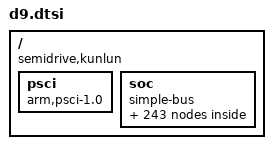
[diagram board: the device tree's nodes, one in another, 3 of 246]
/*
 * Semidrive D9 platform DTS file
 *
 * Copyright (C) 2021, Semidrive  Communications Inc.
 *
 * This file is licensed under a dual GPLv2 or X11 license.
 */

#include <dt-bindings/interrupt-controller/arm-gic.h>
#include <dt-bindings/display/dpu-sdx9.h>
#include <dt-bindings/clk/x9-clk.h>
#include <dt-bindings/dma/x9-dmac-slave-id.h>
#include <dt-bindings/gpio/gpio.h>
#include <dt-bindings/soc/sdrv-common-reg.h>
#include <dt-bindings/soc/sdrv,scr_signal.h>
#include <dt-bindings/soc/sdrv-pfm-group.h>
#include <dt-bindings/thermal/thermal.h>
#include "d9_clk_base.dtsi"
#include "d9_opp.dtsi"
/ {
	compatible = "semidrive,kunlun";
	#address-cells = <2>;
	#size-cells = <2>;

	psci: psci {
		compatible	= "arm,psci-1.0";
		method		= "smc";
		cpu_on		= <0xc4000003>;
		cpu_off		= <0x84000002>;
		cpu_suspend	= <0xc4000001>;
	};

	soc {
		compatible = "simple-bus";
		#address-cells = <2>;
		#size-cells = <2>;
		ranges;

		smmu: smmu@35800000 {
			compatible = "arm,smmu-v3";
			reg = <0x0 0x35800000 0x0 0x800000>;
			interrupts = <0 277 IRQ_TYPE_EDGE_RISING>,
					<0 285 IRQ_TYPE_EDGE_RISING>,
					<0 278 IRQ_TYPE_EDGE_RISING>,
					<0 280 IRQ_TYPE_EDGE_RISING>;
			interrupt-names = "eventq", "priq", "cmdq-sync", "gerror";
			#iommu-cells = <1>;
			status = "disabled";
		};

		uart1: serial@300f0000 {
			compatible = "snps,dw-apb-uart";
			reg = <0 0x300f0000 0 0x100>;
			reg-shift=<2>;
			reg-io-width=<4>;
			interrupts = <0 16 4>;
			clock-frequency=<80000000>;
/*			clocks = <&UART_SEC1_10>;*/
			clock-names = "baudclk";
			status = "disabled";
		};

		uart2: serial@30100000 {
			compatible = "snps,dw-apb-uart";
			reg = <0 0x30100000 0 0x100>;
			reg-shift=<2>;
			reg-io-width=<4>;
			interrupts = <0 17 4>;
			clock-frequency=<80000000>;
/*			clocks = <&UART_SEC1_10>;*/
			clock-names = "baudclk";
			status = "disabled";
		};

		uart4: serial@30120000 {
			compatible = "snps,dw-apb-uart";
			reg = <0 0x30120000 0 0x100>;
			reg-shift=<2>;
			reg-io-width=<4>;
			interrupts = <0 19 4>;
			clock-frequency=<80000000>;
/*			clocks = <&UART_SEC1_10>;*/
			clock-names = "baudclk";
			status = "disabled";
		};

		uart5: serial@30130000 {
			compatible = "snps,dw-apb-uart";
			reg = <0 0x30130000 0 0x100>;
			reg-shift=<2>;
			reg-io-width=<4>;
			interrupts = <0 20 4>;
			clock-frequency=<80000000>;
/*			clocks = <&UART_SEC1_10>;*/
			clock-names = "baudclk";
			status = "disabled";
		};

		uart6: serial@30140000 {
			compatible = "snps,dw-apb-uart";
			reg = <0 0x30140000 0 0x100>;
			reg-shift=<2>;
			reg-io-width=<4>;
			interrupts = <0 21 4>;
			clock-frequency=<80000000>;
/*			clocks = <&UART_SEC1_10>;*/
			clock-names = "baudclk";
			status = "disabled";
		};

		uart7: serial@30150000 {
			compatible = "snps,dw-apb-uart";
			reg = <0 0x30150000 0 0x100>;
			reg-shift=<2>;
			reg-io-width=<4>;
			interrupts = <0 22 4>;
			clock-frequency=<80000000>;
/*			clocks = <&UART_SEC1_10>;*/
			clock-names = "baudclk";
			status = "disabled";
		};

		uart8: serial@30160000 {
			compatible = "snps,dw-apb-uart";
			reg = <0 0x30160000 0 0x100>;
			reg-shift=<2>;
			reg-io-width=<4>;
			interrupts = <0 23 4>;
			clock-frequency=<80000000>;
/*			clocks = <&UART_SEC1_10>;*/
			clock-names = "baudclk";
			status = "disabled";
		};

		uart9: serial@304c0000 {
			compatible = "snps,dw-apb-uart";
			reg = <0 0x304c0000 0 0x100>;
			reg-shift=<2>;
			reg-io-width=<4>;
			interrupts = <0 24 4>;
			clock-frequency=<60000000>;
			clocks = <&UART_SEC0_9>;
			clock-names = "baudclk";
			status = "disabled";
		};

		uart10: serial@304d0000 {
			compatible = "snps,dw-apb-uart";
			reg = <0 0x304d0000 0 0x100>;
			reg-shift=<2>;
			reg-io-width=<4>;
			interrupts = <0 25 4>;
			clock-frequency=<60000000>;
			clocks = <&UART_SEC1_10>;
			clock-names = "baudclk";
			status = "disabled";
		};

		uart11: serial@304e0000 {
			compatible = "snps,dw-apb-uart";
			reg = <0 0x304e0000 0 0x100>;
			reg-shift=<2>;
			reg-io-width=<4>;
			interrupts = <0 26 4>;
			clock-frequency=<60000000>;
			clocks = <&UART_SEC0_11>;
			clock-names = "baudclk";
			status = "disabled";
		};

		uart12: serial@304f0000 {
			compatible = "snps,dw-apb-uart";
			reg = <0 0x304f0000 0 0x100>;
			reg-shift=<2>;
			reg-io-width=<4>;
			interrupts = <0 27 4>;
			clock-frequency=<60000000>;
			clocks = <&UART_SEC1_12>;
			clock-names = "baudclk";
			status = "disabled";
		};

		uart13: serial@30500000 {
			compatible = "snps,dw-apb-uart";
			reg = <0 0x30500000 0 0x100>;
			reg-shift=<2>;
			reg-io-width=<4>;
			interrupts = <0 28 4>;
			clock-frequency=<60000000>;
			clocks = <&UART_SEC0_13>;
			clock-names = "baudclk";
			status = "disabled";
		};

		uart14: serial@30510000 {
			compatible = "snps,dw-apb-uart";
			reg = <0 0x30510000 0 0x100>;
			reg-shift=<2>;
			reg-io-width=<4>;
			interrupts = <0 29 4>;
			clock-frequency=<60000000>;
			clocks = <&UART_SEC1_14>;
			clock-names = "baudclk";
			status = "disabled";
		};

		uart15: serial@30520000 {
			compatible = "snps,dw-apb-uart";
			reg = <0 0x30520000 0 0x100>;
			reg-shift=<2>;
			reg-io-width=<4>;
			interrupts = <0 30 4>;
			clock-frequency=<60000000>;
			clocks = <&UART_SEC0_15>;
			clock-names = "baudclk";
			status = "disabled";
		};

		uart16: serial@30530000 {
			compatible = "snps,dw-apb-uart";
			reg = <0 0x30530000 0 0x100>;
			reg-shift=<2>;
			reg-io-width=<4>;
			interrupts = <0 31 4>;
			clock-frequency=<60000000>;
			clocks = <&UART_SEC1_16>;
			clock-names = "baudclk";
			status = "disabled";
		};

		generic_timer: timer {
			compatible = "arm,armv8-timer";
			interrupts = <1 13 (GIC_CPU_MASK_SIMPLE(6) | IRQ_TYPE_LEVEL_LOW)>,
				<1 14 (GIC_CPU_MASK_SIMPLE(6) | IRQ_TYPE_LEVEL_LOW)>,
				<1 11 (GIC_CPU_MASK_SIMPLE(6) | IRQ_TYPE_LEVEL_LOW)>,
				<1 10 (GIC_CPU_MASK_SIMPLE(6) | IRQ_TYPE_LEVEL_LOW)>;
			clock-frequency = <SYS_CNT_FREQ>;
			status = "disabled";
		};

		timer3: timer@0x308b0000 {
			compatible = "sd,sd-timer", "sd,sd-pwm-capture";
			#address-cells = <2>;
			#size-cells = <2>;
			reg = <0 0x308B0000 0 0x10000>;
			interrupts = <0 197 4>;
			clock-frequency = <24000000>;
			clocks=<&TIMER3>;
			status = "disabled";
		};

		timer4: timer@0x308c0000 {
			compatible = "sd,sd-timer", "sd,sd-pwm-capture";
			#address-cells = <2>;
			#size-cells = <2>;
			reg = <0 0x308C0000 0 0x10000>;
			interrupts = <0 199 4>;
			clock-frequency = <24000000>;
			clocks=<&TIMER4>;
			status = "disabled";
		};

		timer5: timer@0x308d0000 {
			compatible = "sd,sd-timer", "sd,sd-pwm-capture";
			#address-cells = <2>;
			#size-cells = <2>;
			reg = <0 0x308D0000 0 0x10000>;
			interrupts = <0 201 4>;
			clock-frequency = <24000000>;
			clocks=<&TIMER5>;
			status = "disabled";
		};

		timer6: timer@0x308e0000 {
			compatible = "sd,sd-timer", "sd,sd-pwm-capture";
			#address-cells = <2>;
			#size-cells = <2>;
			reg = <0 0x308E0000 0 0x10000>;
			interrupts = <0 203 4>;
			clock-frequency = <24000000>;
			clocks=<&TIMER6>;
			status = "disabled";
		};

		timer7: timer@0x308f0000 {
			compatible = "sd,sd-timer", "sd,sd-pwm-capture";
			#address-cells = <2>;
			#size-cells = <2>;
			reg = <0 0x308F0000 0 0x10000>;
			interrupts = <0 205 4>;
			clock-frequency = <24000000>;
			clocks=<&TIMER7>;
			status = "disabled";
		};

		timer8: timer@0x30900000 {
			compatible = "sd,sd-timer", "sd,sd-pwm-capture";
			#address-cells = <2>;
			#size-cells = <2>;
			reg = <0 0x30900000 0 0x10000>;
			interrupts = <0 207 4>;
			clock-frequency = <24000000>;
			clocks=<&TIMER8>;
			status = "disabled";
		};

		adc_ap: adc@0x30860000 {
			compatible = "sdrv,sdrv-adc";
			reg = <0 0x30860000 0 0x10000>;
			interrupts = <GIC_SPI 208 IRQ_TYPE_LEVEL_HIGH>;
            		#io-channel-cells = <1>;
			clocks = <&ADC>;
			clock-names = "adc-clk";
			status = "disabled";
		};

		pwm1:pwm@301a0000 {
				compatible = "sd,sd-pwm-playback";
				#address-cells = <2>;
				#size-cells = <2>;
				reg = <0 0x301a0000 0 0x10000>;
				interrupts = <0 209 4>;
				clock-frequency = <398000000>;
				clocks=<&PWM1>;
				clock-names = "plbkclk";
				status = "disabled";
		};

		pwm2:pwm@301b0000 {
				compatible = "sd,sd-pwm-playback";
				#address-cells = <2>;
				#size-cells = <2>;
				reg = <0 0x301b0000 0 0x10000>;
				interrupts = <0 210 4>;
				clock-frequency = <398000000>;
				clocks=<&PWM2>;
				clock-names = "plbkclk";
				status = "disabled";
		};

		pwm3:pwm@0x30910000 {
			compatible = "sd,sd-pwm-playback";
			#address-cells = <2>;
			#size-cells = <2>;
			reg = <0 0x30910000 0 0x10000>;
			interrupts = <0 211 4>;
			clock-frequency = <398000000>;
			clocks=<&PWM3>;
			clock-names = "plbkclk";
			status = "disabled";
		};

		pwm4:pwm@0x30920000 {
			compatible = "sd,sd-pwm-playback";
			#address-cells = <2>;
			#size-cells = <2>;
			reg = <0 0x30920000 0 0x10000>;
			interrupts = <0 212 4>;
			clock-frequency = <398000000>;
			clocks=<&PWM4>;
			clock-names = "plbkclk";
			status = "disabled";
		};

		pwm5:pwm@0x30930000 {
			compatible = "sd,sd-pwm-playback";
			#address-cells = <2>;
			#size-cells = <2>;
			reg = <0 0x30930000 0 0x10000>;
			interrupts = <0 213 4>;
			clock-frequency = <398000000>;
			clocks=<&PWM5>;
			clock-names = "plbkclk";
			status = "disabled";
		};

		pwm6:pwm@0x30940000 {
			compatible = "sd,sd-pwm-playback";
			#address-cells = <2>;
			#size-cells = <2>;
			reg = <0 0x30940000 0 0x10000>;
			interrupts = <0 214 4>;
			clock-frequency = <398000000>;
			clocks=<&PWM6>;
			clock-names = "plbkclk";
			status = "disabled";
		};

		pwm7:pwm@0x30950000 {
			compatible = "sd,sd-pwm-playback";
			#address-cells = <2>;
			#size-cells = <2>;
			reg = <0 0x30950000 0 0x10000>;
			interrupts = <0 215 4>;
			clock-frequency = <398000000>;
			clocks=<&PWM7>;
			clock-names = "plbkclk";
			status = "disabled";
		};

		pwm8:pwm@0x30960000 {
			compatible = "sd,sd-pwm-playback";
			#address-cells = <2>;
			#size-cells = <2>;
			reg = <0 0x30960000 0 0x10000>;
			interrupts = <0 216 4>;
			clock-frequency = <398000000>;
			clocks=<&PWM8>;
			clock-names = "plbkclk";
			status = "disabled";
		};

		i2c1:i2c@300b0000 {
			compatible = "snps,designware-i2c";
			reg = <0x0 0x300b0000 0x0 0x1000>;
			interrupts = <0 32 4>;
			#address-cells = <1>;
			#size-cells = <0>;
			clocks=<&I2C_SEC0_5>;
			clock-names = "i2c-clk";
			#clock-frequency = <100000>;
			timeout = <10>; /* ms */
			status = "disabled";
		};

		i2c2:i2c@300c0000 {
			compatible = "snps,designware-i2c";
			reg = <0x0 0x300c0000 0x0 0x1000>;
			interrupts = <0 33 4>;
			#address-cells = <1>;
			#size-cells = <0>;
			clocks=<&I2C_SEC0_5>;
			clock-names = "i2c-clk";
			#clock-frequency = <100000>;
			timeout = <10>; /* ms */
			status = "disabled";
		};

		i2c3:i2c@300d0000 {
			compatible = "snps,designware-i2c";
			reg = <0x0 0x300d0000 0x0 0x1000>;
			interrupts = <0 34 4>;
			#address-cells = <1>;
			#size-cells = <0>;
			clocks=<&I2C_SEC0_7>;
			clock-names = "i2c-clk";
			#clock-frequency = <100000>;
			timeout = <10>; /* ms */
			status = "disabled";
		};


		i2c4:i2c@300e0000 {
			compatible = "snps,designware-i2c";
			reg = <0x0 0x300e0000 0x0 0x1000>;
			interrupts = <0 35 4>;
			#address-cells = <1>;
			#size-cells = <0>;
			clocks=<&I2C_SEC0_7>;
			clock-names = "i2c-clk";
			#clock-frequency = <100000>;
			timeout = <10>; /* ms */
			status = "disabled";
		};

		i2c5:i2c@30ac0000 {
			compatible = "snps,designware-i2c";
			reg = <0x0 0x30ac0000 0x0 0x1000>;
			interrupts = <0 36 4>;
			#address-cells = <1>;
			#size-cells = <0>;
			clocks=<&I2C_SEC0_5>;
			clock-names = "i2c-clk";
			#clock-frequency = <100000>;
			timeout = <10>; /* ms */
			status = "disabled";
		};

		i2c6:i2c@30ad0000 {
			compatible = "snps,designware-i2c";
			reg = <0x0 0x30ad0000 0x0 0x1000>;
			interrupts = <0 37 4>;
			#address-cells = <1>;
			#size-cells = <0>;
			clocks=<&I2C_SEC1_6>;
			clock-names = "i2c-clk";
			#clock-frequency = <100000>;
			timeout = <10>; /* ms */
			status = "disabled";
		};

		i2c7:i2c@30ae0000 {
			compatible = "snps,designware-i2c";
			reg = <0x0 0x30ae0000 0x0 0x1000>;
			interrupts = <0 38 4>;
			#address-cells = <1>;
			#size-cells = <0>;
			clocks=<&I2C_SEC0_7>;
			clock-names = "i2c-clk";
			#clock-frequency = <100000>;
			timeout = <10>; /* ms */
			status = "disabled";
		};

		i2c8:i2c@30af0000 {
			compatible = "snps,designware-i2c";
			reg = <0x0 0x30af0000 0x0 0x1000>;
			interrupts = <0 39 4>;
			#address-cells = <1>;
			#size-cells = <0>;
			clocks=<&I2C_SEC1_8>;
			clock-names = "i2c-clk";
			#clock-frequency = <100000>;
			timeout = <10>; /* ms */
			status = "disabled";
		};

		i2c9:i2c@30b00000 {
			compatible = "snps,designware-i2c";
			reg = <0x0 0x30b00000 0x0 0x1000>;
			interrupts = <0 40 4>;
			#address-cells = <1>;
			#size-cells = <0>;
			clocks=<&I2C_SEC0_9>;
			clock-names = "i2c-clk";
			#clock-frequency = <100000>;
			timeout = <10>; /* ms */
			status = "disabled";
		};

		i2c10:i2c@30b10000 {
			compatible = "snps,designware-i2c";
			reg = <0x0 0x30b10000 0x0 0x1000>;
			interrupts = <0 41 4>;
			#address-cells = <1>;
			#size-cells = <0>;
			clocks=<&I2C_SEC1_10>;
			clock-names = "i2c-clk";
			#clock-frequency = <100000>;
			timeout = <10>; /* ms */
			status = "disabled";
		};

		i2c11:i2c@30b20000 {
			compatible = "snps,designware-i2c";
			reg = <0x0 0x30b20000 0x0 0x1000>;
			interrupts = <0 42 4>;
			#address-cells = <1>;
			#size-cells = <0>;
			clocks=<&I2C_SEC0_11>;
			clock-names = "i2c-clk";
			clock-frequency = <100000>;
			timeout = <10>; /* ms */
			status = "disabled";
		};

		i2c12:i2c@30b30000 {
			compatible = "snps,designware-i2c";
			reg = <0x0 0x30b30000 0x0 0x1000>;
			interrupts = <0 43 4>;
			#address-cells = <1>;
			#size-cells = <0>;
			clocks=<&I2C_SEC1_12>;
			clock-names = "i2c-clk";
			#clock-frequency = <100000>;
			timeout = <10>; /* ms */
			status = "disabled";
		};

		spi1: spi@30380000 { /* physical spi num is 1 */
			compatible = "snps,dw-apb-ssi";
			reg = <0x0 0x30380000 0x0 0x10000>;
			interrupts = <0 48 4>;
			clocks=<&SPI_SEC0_5>;
			num-cs = <1>;
			reg-io-width = <4>;
			bus-num = <5>;
			sdrv,scr_opmode = <0>;
			#address-cells = <1>;
			#size-cells = <0>;
			status = "disabled";
		};


		spi2: spi@30390000 { /* physical spi num is 2 */
			compatible = "snps,dw-apb-ssi";
			reg = <0x0 0x30390000 0x0 0x10000>;
			interrupts = <0 49 4>;
			clocks=<&SPI_SEC0_5>;
			num-cs = <1>;
			reg-io-width = <4>;
			bus-num = <4>;
			sdrv,scr_opmode = <0>;
			#address-cells = <1>;
			#size-cells = <0>;
			status = "disabled";
		};

		spi3: spi@303A0000 { /* physical spi num is 3 */
			compatible = "snps,dw-apb-ssi";
			reg = <0x0 0x303A0000 0x0 0x10000>;
			interrupts = <0 50 4>;
			clocks=<&SPI_SEC0_5>;
			num-cs = <1>;
			reg-io-width = <4>;
			bus-num = <6>;
			sdrv,scr_opmode = <0>;
			#address-cells = <1>;
			#size-cells = <0>;
			status = "disabled";
		};

		spi4: spi@303B0000 { /* physical spi num is 4 */
			compatible = "snps,dw-apb-ssi";
			reg = <0x0 0x303B0000 0x0 0x10000>;
			interrupts = <0 51 4>;
			clocks=<&SPI_SEC0_5>;
			num-cs = <1>;
			reg-io-width = <4>;
			bus-num = <7>;
			sdrv,scr_opmode = <0>;
			#address-cells = <1>;
			#size-cells = <0>;
			status = "disabled";
		};

		spi5: spi@309A0000 { /* physical spi num is 5 */
			compatible = "snps,dw-apb-ssi";
			reg = <0x0 0x309A0000 0x0 0x10000>;
			interrupts = <0 52 4>;
			clocks=<&SPI_SEC0_5>;
			num-cs = <1>;
			reg-io-width = <4>;
			bus-num = <0>;
			sdrv,scr_opmode = <SCR_SEC__spi5_i_opmode>;
			#address-cells = <1>;
			#size-cells = <0>;
			status = "disabled";
		};

		spi6: spi@309B0000 { /* physical spi num is 6 */
			compatible = "snps,dw-apb-ssi";
			reg = <0x0 0x309B0000 0x0 0x10000>;
			interrupts = <0 53 4>;
			clocks=<&SPI_SEC1_6>;
			num-cs = <1>;
			reg-io-width = <4>;
			bus-num = <1>;
			sdrv,scr_opmode = <SCR_SEC__spi6_i_opmode>;
			#address-cells = <1>;
			#size-cells = <0>;
			status = "disabled";
		};

		spi7: spi@309C0000 { /* physical spi num is 7 */
			compatible = "snps,dw-apb-ssi";
			reg = <0x0 0x309C0000 0x0 0x10000>;
			interrupts = <0 54 4>;
			clocks=<&SPI_SEC0_7>;
			num-cs = <1>;
			reg-io-width = <4>;
			bus-num = <2>;
			sdrv,scr_opmode = <SCR_SEC__spi7_i_opmode>;
			#address-cells = <1>;
			#size-cells = <0>;
			status = "disabled";
		};

		spi8: spi@309D0000 { /* physical spi num is 8 */
			compatible = "snps,dw-apb-ssi";
			reg = <0x0 0x309D0000 0x0 0x10000>;
			interrupts = <0 55 4>;
			clocks=<&SPI_SEC1_8>;
			num-cs = <1>;
			reg-io-width = <4>;
			bus-num = <3>;
			sdrv,scr_opmode = <SCR_SEC__spi8_i_opmode>;
			#address-cells = <1>;
			#size-cells = <0>;
			status = "disabled";
		};

		usbdrd3_1: usb3@31220000 {
			compatible = "semidrive,dwc3";
			#address-cells = <2>;
			#size-cells = <2>;
			ranges;
			clocks = <&HIS_BUS_2_USB1>, <&HIS_BUS_3_USB1>;
			clock-names = "axi_clk", "apb_clk";
			status = "disabled";

			usb1: dwc3 {
				compatible = "snps,dwc3";
				reg = <0x0 0x31220000 0x0 0x20000>;
				interrupts = <0 72 4>;
				dr_mode = "peripheral";
				phy_type = "utmi_wide";
				phys = <&usbdrd_phy1 0>;
				phy-names = "usb3-phy";
				snps,dis_u3_susphy_quirk;
				maximum-speed = "high-speed";
				extcon = <&usb3_id1>;
				status = "disabled";
			};
		};

		usb3_id1: usb3-id1 {
			compatible = "linux,extcon-usb-gpio";
			no_id_gpio_quirk;
		};

		usbdrd_phy1: phy@31240000 {
			compatible = "semidrive,usb-phy";
			reg = <0x0 0x31240000 0x0 0x20000>;
			#phy-cells = <1>;
		};

		usbdrd3_2: usb3@31260000 {
			compatible = "semidrive,dwc3";
			#address-cells = <2>;
			#size-cells = <2>;
			ranges;
			clocks = <&HIS_BUS_2_USB2>, <&HIS_BUS_3_USB2>;
			clock-names = "axi_clk", "apb_clk";
			status = "disabled";

			usb2: dwc3 {
				compatible = "snps,dwc3";
				reg = <0x0 0x31260000 0x0 0x20000>;
				interrupts = <0 75 4>;
				dr_mode = "host";
				phy_type = "utmi_wide";
				phys = <&usbdrd_phy2 0>;
				phy-names = "usb3-phy";
				snps,dis_u3_susphy_quirk;
				status = "disabled";
			};
		};

		usbdrd_phy2: phy@31280000 {
			compatible = "semidrive,usb-phy";
			reg = <0x0 0x31280000 0x0 0x20000>;
			#phy-cells = <1>;
		};

		/* This dmac is reserved for sec core, just for test in ap domain. */
		dmac2: dma@35510000 {
			compatible = "snps,axi-dma-1.01a";
			reg = <0 0x35510000 0 0x10000>, /* dma reg address */
			     <0 0x30440000 0 0x10000>;  /*dma mux address for mux mode*/
			#dma-cells = <1>;
			clocks = <&HIS_BUS_2>, <&HIS_BUS_2>;
			clock-names = "core-clk", "cfgr-clk";
			interrupts = <0 1 4>;

			dma-channels = <8>;
			snps,dma-masters = <1>;
			snps,data-width = <3>;
			snps,block-size = <0x10000 0x10000 0x10000 0x10000 0x10000 0x10000 0x10000 0x10000>;
			snps,priority = <0 1 2 3 4 5 6 7>;
			snps,axi-max-burst-len = <4>;
			status = "disabled";
		};

		dmac3: dma@35520000 {
			compatible = "snps,axi-dma-1.01a";
			reg = <0 0x35520000 0 0x10000>, //dma reg address
			     <0 0x30450000 0 0x10000>;  //dma mux address for mux mode
			#dma-cells = <1>;
			clocks = <&HIS_BUS_2>, <&HIS_BUS_2>;//
			clock-names = "core-clk", "cfgr-clk";
			interrupts = <0 2 4>;

			dma-channels = <8>;
			snps,dma-masters = <1>;
			snps,data-width = <3>;
			snps,block-size = <0x10000 0x10000 0x10000 0x10000 0x10000 0x10000 0x10000 0x10000>;
			snps,priority = <0 1 2 3 4 5 6 7>;
			snps,axi-max-burst-len = <4>;
			status = "disabled";
		};

		dmac4: dma@35530000 {
			compatible = "snps,axi-dma-1.01a";
			reg = <0 0x35530000 0 0x10000>, //dma reg address
			     <0 0x30460000 0 0x10000>;  //dma mux address for mux mode
			#dma-cells = <1>;
			clocks = <&HIS_BUS_2>, <&HIS_BUS_2>;//
			clock-names = "core-clk", "cfgr-clk";
			interrupts = <0 3 4>;

			dma-channels = <8>;
			snps,dma-masters = <1>;
			snps,data-width = <3>;
			snps,block-size = <0x10000 0x10000 0x10000 0x10000 0x10000 0x10000 0x10000 0x10000>;
			snps,priority = <0 1 2 3 4 5 6 7>;
			snps,axi-max-burst-len = <4>;
			status = "disabled";
		};

		dmac5: dma@35540000 {
			compatible = "snps,axi-dma-1.01a";
			reg = <0 0x35540000 0 0x10000>, //dma reg address
			     <0 0x30470000 0 0x10000>;  //dma mux address for mux mode
			#dma-cells = <1>;
			clocks = <&HIS_BUS_2>, <&HIS_BUS_2>;//
			clock-names = "core-clk", "cfgr-clk";
			interrupts = <0 4 4>;

			dma-channels = <8>;
			snps,dma-masters = <1>;
			snps,data-width = <3>;
			snps,block-size = <0x10000 0x10000 0x10000 0x10000 0x10000 0x10000 0x10000 0x10000>;
			snps,priority = <0 1 2 3 4 5 6 7>;
			snps,axi-max-burst-len = <4>;
			status = "disabled";
		};

		dmac6: dma@35550000 {
			compatible = "snps,axi-dma-1.01a";
			reg = <0 0x35550000 0 0x10000>, //dma reg address
			     <0 0x30480000 0 0x10000>;  //dma mux address for mux mode
			#dma-cells = <1>;
			clocks = <&HIS_BUS_2>, <&HIS_BUS_2>;//
			clock-names = "core-clk", "cfgr-clk";
			interrupts = <0 5 4>;

			dma-channels = <8>;
			snps,dma-masters = <1>;
			snps,data-width = <3>;
			snps,block-size = <0x10000 0x10000 0x10000 0x10000 0x10000 0x10000 0x10000 0x10000>;
			snps,priority = <0 1 2 3 4 5 6 7>;
			snps,axi-max-burst-len = <4>;
			status = "disabled";
		};

		dmac7: dma@35560000 {
			compatible = "snps,axi-dma-1.01a";
			reg = <0 0x35560000 0 0x10000>, //dma reg address
			     <0 0x30490000 0 0x10000>;  //dma mux address for mux mode
			#dma-cells = <1>;
			clocks = <&HIS_BUS_2>, <&HIS_BUS_2>;//
			clock-names = "core-clk", "cfgr-clk";
			interrupts = <0 6 4>;

			dma-channels = <8>;
			snps,dma-masters = <1>;
			snps,data-width = <3>;
			snps,block-size = <0x10000 0x10000 0x10000 0x10000 0x10000 0x10000 0x10000 0x10000>;
			snps,priority = <0 1 2 3 4 5 6 7>;
			snps,axi-max-burst-len = <4>;
			status = "disabled";
		};

		dmac8: dma@35570000 {
			compatible = "snps,axi-dma-1.01a";
			reg = <0 0x35570000 0 0x10000>, //dma reg address
			     <0 0x304a0000 0 0x10000>;  //dma mux address for mux mode
			#dma-cells = <1>;
			clocks = <&HIS_BUS_2>, <&HIS_BUS_2>;//
			clock-names = "core-clk", "cfgr-clk";
			interrupts = <0 7 4>;

			dma-channels = <8>;
			snps,dma-masters = <1>;
			snps,data-width = <3>;
			snps,block-size = <0x10000 0x10000 0x10000 0x10000 0x10000 0x10000 0x10000 0x10000>;
			snps,priority = <0 1 2 3 4 5 6 7>;
			snps,axi-max-burst-len = <4>;
			status = "disabled";
		};

		afe_i2s_sc3: i2s@30600000 {
			compatible = "semidrive,x9-i2s-sc";
			reg = <0 0x30600000 0 0x200>;
			interrupts = <0 60 4>;
			clocks=<&I2S_SC3>,<&I2S_MCLK3>;
			clock-names = "i2s-clk","i2s-mclk";
			semidrive,full-duplex = <1>;
			status = "disabled";
		};

		afe_i2s_sc4: i2s@30610000 {
			compatible = "semidrive,x9-i2s-sc";
			reg = <0 0x30610000 0 0x200>;
			interrupts = <0 61 4>;
			clocks=<&I2S_SC4>,<&I2S_MCLK3>;
			clock-names = "i2s-clk","i2s-mclk";
			semidrive,full-duplex = <1>;
			status = "disabled";
		};

		afe_i2s_sc5: i2s@30620000 {
			compatible = "semidrive,x9-i2s-sc";
			reg = <0 0x30620000 0 0x200>;
			interrupts = <0 62 4>;
			clocks=<&I2S_SC5>,<&I2S_MCLK3>;
			clock-names = "i2s-clk","i2s-mclk";
			semidrive,full-duplex = <1>;
			status = "disabled";
		};

		afe_i2s_sc6: i2s@30630000 {
			compatible = "semidrive,x9-i2s-sc";
			reg = <0 0x30630000 0 0x200>;
			interrupts = <0 63 4>;
			clocks=<&I2S_SC6>,<&I2S_MCLK3>;
			clock-names = "i2s-clk","i2s-mclk";
			semidrive,full-duplex = <1>;
			status = "disabled";
		};

		afe_i2s_sc7: i2s@30640000 {
			compatible = "semidrive,x9-i2s-sc";
			reg = <0 0x30640000 0 0x200>;
			interrupts = <0 64 4>;
			clocks=<&I2S_SC7>,<&I2S_MCLK2>;
			clock-names = "i2s-clk","i2s-mclk";
			semidrive,full-duplex = <1>;
			status = "disabled";
		};

		afe_i2s_sc8: i2s@30650000 {
			compatible = "semidrive,x9-i2s-sc";
			reg = <0 0x30650000 0 0x200>;
			interrupts = <0 65 4>;
			clocks=<&I2S_SC8>,<&I2S_MCLK2>;
			clock-names = "i2s-clk","i2s-mclk";
			semidrive,full-duplex = <1>;
			status = "disabled";
		};

		afe_i2s_mc1: i2s_mc@305c0000 {
			compatible = "semidrive,x9-i2s-mc";
			reg = <0 0x305c0000 0 0x200>;
			interrupts = <0 98 4>;
			clocks=<&I2S_MC1>,<&I2S_MCLK2>;
			clock-names = "i2s-mc-clk","i2s-mc-mclk";
			status = "disabled";
		};

		afe_i2s_mc2: i2s_mc@305d0000 {
			compatible = "semidrive,x9-i2s-mc";
			reg = <0 0x305d0000 0 0x200>;
			interrupts = <0 99 4>;
			clocks=<&I2S_MC2>,<&I2S_MCLK2>;
			clock-names = "i2s-mc-clk","i2s-mc-mclk";
			status = "disabled";
		};

		pinctrl: pinctrl@38500000 {
			compatible = "semidrive,kunlun-pinctrl";
			reg = <0x0 0x38500000 0x0 0x10000>;
		};

		sram: soc_sram {
			compatible = "soc-sram";
			#address-cells = <2>;
			#size-cells = <2>;
			reg = <0x0 0x180000 0x0 0x40000>,
				<0x0 0x1c0000 0x0 0x40000>;
			reg-names = "sram3", "sram4";
		};

		vpu2:coda988@31430000 {
			compatible = "semidrive,coda988";
			#address-cells = <2>;
			#size-cells = <2>;
			reg = <0x0 0x31430000 0x0 0x4000>,
				  <0x0 0xD00000   0x0 0x2A000>;
			reg-names = "register", "inter_sram";
			vpu2,sram = <&sram>;
			sram-index = <1>; /* index to sram4 */
			clocks = <&VPU_BUS_0_VPU2>;
			clock-names = "core-clk";
			clock-frequency = <666000000>;
			interrupts = <0 168 4>;
			sdrv,scr_signal = <SCR_SEC__vpu2_i_linebuffer_cfg_1_0>;
			status = "disabled";
		};

		jpu:codaj12@31420000 {
			compatible = "semidrive,codaj12";
			#address-cells = <2>;
			#size-cells = <2>;
			reg = <0x0 0x31420000 0x0 0x1000>;
			reg-names = "register";
			clocks = <&VPU_BUS_0_MJPEG>,<&MJPEG_0>;
			clock-names = "core-aclk","core-cclk";
			clock-frequency = <666000000>,<532800000>;
			interrupts = <0 169 4>;
			status = "disabled";
		};

		gpu2:gpu2@34e00000 {
			compatible = "imagination,pvr-rogue";
			reg = <0x0 0x34e00000 0x0 0x80000>;
			interrupts = <0 158 4>;
			clock-frequency = <800000000>;
			clocks = <&GPU2_0>;
			clock-names = "gpucoreclk";
			operating-points-v2 = <&gpu1_opp_table>;
			status = "disabled";
		};

		regulators {
			compatible = "simple-bus";
			#address-cells = <1>;
			#size-cells = <0>;

			vmmc_3v3: regulator@0{
				compatible = "regulator-fixed";
				reg = <0>;
				regulator-name = "VMEM_VDD_3.3V";
				regulator-min-microvolt = <3300000>;
				regulator-max-microvolt = <3300000>;
			};

			vqmmc_1v8: regulator@1{
				compatible = "regulator-fixed";
				reg = <1>;
				regulator-name = "VMEM_VDDIO_1.8V";
				regulator-min-microvolt = <1800000>;
				regulator-max-microvolt = <1800000>;
			};

			vqmmc_3v3: regulator@2{
				compatible = "regulator-fixed";
				reg = <2>;
				regulator-name = "VMEM_VDDIO_3.3V";
				regulator-min-microvolt = <3300000>;
				regulator-max-microvolt = <3300000>;
			};
		};

		sdhci1: sdhci@34180000 {
			compatible = "snps,dwcmshc-sdhci";
			reg = <0 0x34180000 0 0x10000>;
			interrupts = <GIC_SPI 110 IRQ_TYPE_LEVEL_HIGH>, <GIC_SPI 111 IRQ_TYPE_LEVEL_HIGH>;
			sdrv,scr_signals_ddr = <SCR_SEC__mshc1_ddr_mode>;
			#clock-cells = <1>;
			clocks = <&EMMC1>;
			clock-names = "core";
			max-frequency = <200000000>;
			vmmc-supply = <&vmmc_3v3>;
			vqmmc-supply = <&vqmmc_1v8>;
			cap-mmc-hw-reset;
			status = "disabled";
		};

		sdhci2: sdhci@34190000 {
			compatible = "snps,dwcmshc-sdhci";
			reg = <0 0x34190000 0 0x10000>;
			interrupts = <GIC_SPI 112 IRQ_TYPE_LEVEL_HIGH>, <GIC_SPI 113 IRQ_TYPE_LEVEL_HIGH>;
			sdrv,scr_signals_ddr = <SCR_SEC__mshc2_ddr_mode>;
			#clock-cells = <1>;
			clocks = <&EMMC2>;
			clock-names = "core";
			max-frequency = <200000000>;
			vmmc-supply = <&vmmc_3v3>;
			vqmmc-supply = <&vqmmc_1v8>;
			status = "disabled";
		};

		sdhci3: sdhci@341a0000 {
			compatible = "snps,dwcmshc-sdhci";
			reg = <0 0x341a0000 0 0x10000>;
			interrupts = <GIC_SPI 114 IRQ_TYPE_LEVEL_HIGH>, <GIC_SPI 115 IRQ_TYPE_LEVEL_HIGH>;
			sdrv,scr_signals_ddr = <SCR_SEC__mshc3_ddr_mode>;
			vmmc-supply = <&vmmc_3v3>;
			vqmmc-supply = <&vqmmc_1v8>;
			status = "disabled";
		};

		sdhci4: sdhci@341b0000 {
			compatible = "snps,dwcmshc-sdhci";
			reg = <0 0x341b0000 0 0x10000>;
			interrupts = <GIC_SPI 116 IRQ_TYPE_LEVEL_HIGH>, <GIC_SPI 117 IRQ_TYPE_LEVEL_HIGH>;
			sdrv,scr_signals_ddr = <SCR_SEC__mshc4_ddr_mode>;
			status = "disabled";
		};

		csi0:csi@30cc0000 {
			compatible = "semidrive,sdrv-csi";
			reg = <0x0 0x30CC0000 0x0 0x10000>;
			interrupts = <0 141 4>;
			host_id = <0>;
			status = "disabled";

			ports {
				#address-cells = <1>;
				#size-cells = <0>;

				csi0_stream0: port@0 {
					#address-cells = <1>;
					#size-cells = <0>;
					reg = <0>;
					csi0_stream0_in: endpoint@0 {
						reg = <0>;
					};
				};

				csi0_stream1: port@1 {
					#address-cells = <1>;
					#size-cells = <0>;
					reg = <1>;
					csi0_stream1_in: endpoint@0 {
						reg = <1>;
					};
				};

				csi0_stream2: port@2 {
					#address-cells = <1>;
					#size-cells = <0>;
					reg = <2>;
					csi0_stream2_in: endpoint@0 {
						reg = <2>;
					};
				};

				csi0_stream3: port@3 {
					#address-cells = <1>;
					#size-cells = <0>;
					reg = <3>;
					csi0_stream3_in: endpoint@0 {
						reg = <3>;
					};
				};
			};
		};

		csi2:csi@30ce0000 {
			compatible = "semidrive,sdrv-csi";
			reg = <0x0 0x30CE0000 0x0 0x10000>;
			interrupts = <0 143 4>;
			host_id = <2>;
			status = "disabled";

			ports {
				#address-cells = <1>;
				#size-cells = <0>;

				csi2_stream0: port@0 {
					#address-cells = <1>;
					#size-cells = <0>;
					reg = <0>;
					csi2_stream0_in: endpoint@0 {
						reg = <0>;
					};
				};

				csi2_stream1: port@1 {
					#address-cells = <1>;
					#size-cells = <0>;
					reg = <1>;
					csi2_stream1_in: endpoint@0 {
						reg = <1>;
					};
				};

				csi2_stream2: port@2 {
					#address-cells = <1>;
					#size-cells = <0>;
					reg = <2>;
					csi2_stream2_in: endpoint@0 {
						reg = <2>;
					};
				};

				csi2_stream3: port@3 {
					#address-cells = <1>;
					#size-cells = <0>;
					reg = <3>;
					csi2_stream3_in: endpoint@0 {
						reg = <3>;
					};
				};
			};
		};

		csimipi0:csi-mipi@30d00000 {
			compatible = "semidrive,sdrv-csi-mipi";
			reg = <0x0 0x30d00000 0x0 0x10000>, <0x0 0x30d50000 0x0 0x1000>;
			interrupts = <0 144 4>;
			host_id = <0>;
			status = "disabled";
		};

		csiparallel:csi-parallel@0 {
			compatible = "semidrive,sdrv-csi-parallel";
			status = "disabled";

			port {
				#address-cells = <1>;
				#size-cells = <0>;

				csiparallel0_in: endpoint@0 {
					reg = <0>;
				};

				csiparalle0_out: endpoint@1 {
					reg = <1>;
				};
			};
		};

		ospi2: spi@306d0000 {
			compatible = "sdrv,ospi-nor";
			#address-cells = <1>;
			#size-cells = <0>;
			reg = <0 0x306d0000 0 0x10000>,
			      <0 0x8000000 0 0x4000000>;
			interrupts = <GIC_SPI 57 IRQ_TYPE_LEVEL_HIGH>;
			cdns,fifo-depth = <256>;
			cdns,fifo-width = <4>;
			cdns,trigger-address = <0x3fffe00>;
			clocks = <&OSPI2>;
			status = "disabled";
		};

		mbox: mbox@34040000 {
			compatible = "semidrive,sd-mailbox";
			reg = <0x0 0x34040000 0x0 0x200>,
				<0x0 0x34041000 0x0 0x1000>,
				<0x0 0x34042000 0x0 0x8000>;
			interrupts = <GIC_SPI 232 IRQ_TYPE_LEVEL_HIGH>;
			#mbox-cells = <2>;
			status = "disabled";
		};

		vdsp_ipc: vdsp@0 {
			compatible = "sd,vdsp-ipc";
			mboxes = <&mbox 0x07 0x0705>;
			status = "disabled";
		};

		mbox_test: mbox-test@0 {
			compatible = "mailbox-test";
			mbox-names = "tx", "rx";
			mboxes = <&mbox 0x05 0x0501>, <&mbox 0x05 0x0501>;
			status = "disabled";
		};

		rpmsg0: rpmsg@0 {
			compatible = "sd,rpmsg-vq,rp_saf";
			mboxes = <&mbox 0x13 0x1300>;
			status = "disabled";
		};

		rpmsg1: rpmsg@1 {
			compatible = "sd,rpmsg-vq,rp_sec";
			mboxes = <&mbox 0x14 0x1401>;
			status = "disabled";
		};

		rpmsg2: rpmsg@2 {
			compatible = "sd,rpmsg-vq,rp_mp";
			mboxes = <&mbox 0x18 0x1802>;
			status = "disabled";
		};

		rpmsg3: rpmsg@3 {
			compatible = "sd,rpmsg-vq,rp_ap";
			mboxes = <&mbox 0x19 0x1903>;
			status = "disabled";
		};

		rpmsg4: rpmsg@4 {
			compatible = "sd,rpmsg-vq,rp_ap";
			mboxes = <&mbox 0x19 0x1904>;
			status = "disabled";
		};

		ipcc0: ipcc@0 {
			compatible = "sd,rpmsg-ipcc";
			mboxes = <&mbox 0x33 0x3300>;
			#rpmsg-cells = <2>;
			status = "disabled";
		};

		ipcc1: ipcc@1 {
			compatible = "sd,rpmsg-ipcc";
			mboxes = <&mbox 0x34 0x3401>;
			#rpmsg-cells = <2>;
			status = "disabled";
		};

		ipcc2: ipcc@2 {
			compatible = "sd,rpmsg-ipcc";
			mboxes = <&mbox 0x38 0x3802>;
			#rpmsg-cells = <2>;
			status = "disabled";
		};

		ipcc3: ipcc@3 {
			compatible = "sd,rpmsg-ipcc";
			mboxes = <&mbox 0x39 0x3903>;
			#rpmsg-cells = <2>;
			status = "disabled";
		};

		ipcc4: ipcc@4 {
			compatible = "sd,rpmsg-ipcc";
			mboxes = <&mbox 0x39 0x3904>;
			#rpmsg-cells = <2>;
			status = "disabled";
		};

		hwsema: hwspinlock@34040200 {
			compatible = "semidrive,hwsemaphore";
			reg = <0x0 0x34040000 0x0 0x1000>; /* 0x200 - 0x400 */
			#hwlock-cells = <1>;
			status = "disabled";
		};

		sys_cntr: sys_cntr@0x31400000 {
			compatible = "semidrive,syscntr";
			reg = <0x0 0x31400000 0x0 0x1000>;
			clock-frequency = <SYS_CNT_FREQ>;
			status = "disabled";
		};

		dcf_property:dcf_property@0 {
			compatible = "sd,property";
			status = "disabled";
		};

		dcf_vircan0:dcf_vircan@0 {
			compatible = "sd,vircan";
			status = "disabled";
		};

		dcf_vircan1:dcf_vircan@1 {
			compatible = "sd,vircan";
			status = "disabled";
		};

		dcf_virnet: rpmsg-net {
			compatible = "sd,rpmsg-netdev";
			status     = "disabled";
		};

		g2d: g2d@30c90000 {
			compatible = "semidrive,g2d";
			reg = <0x00 0x30c90000 0x00 0x10000>;
			interrupts = <0 147 4>;
			status = "disabled";
			sdrv,ip = "g2d-r0p1";
		};

		display: display@0 {
			compatible = "semdrive,display-subsystem";
			sdriv,crtc = <&crtc0>;
			status = "disabled";
		};

		dp1: dp1@30d80000 {
			compatible = "sdrv,dp";
			reg = <DP1_BASE DPU_RANGE>;
			interrupts = <0 DP1_IRQ 4>;
			status = "disabled";
			mlc-select = <0>;
			sdrv,ip = "dp-r0p1";
		};

		dc1: dc1@30db0000 {
			compatible = "sdrv,dc";
			reg = <DC1_BASE DPU_RANGE>;
			interrupts = <0 DC1_IRQ 4>;
			status = "disabled";
			sdrv,ip = "dc-r0p1";
			clocks = <&PLL_LVDS1 PLL_DIVA>;
			clock-names = "pll_clk";
		};

		dc2: dc2@30dc0000 {
			compatible = "sdrv,dc";
			reg = <DC2_BASE DPU_RANGE>;
			interrupts = <0 DC2_IRQ 4>;
			status = "disabled";
			sdrv,ip = "dc-r0p1";
			clocks = <&PLL_LVDS2 PLL_DIVA>;
			clock-names = "pll_clk";
		};

		dc3: dc3@30dd0000 {
			compatible = "sdrv,dc";
			reg = <DC3_BASE DPU_RANGE>;
			interrupts = <0 DC3_IRQ 4>;
			status = "disabled";
			sdrv,ip = "dc-r0p1";
			clocks = <&PLL_LVDS3 PLL_DIVA>;
			clock-names = "pll_clk";
		};

		crtc0: crtc0 {
			compatible = "semidrive,kunlun-crtc";
			dpc-master = <&dc1>;
			/* 1 single, 2: duplicate, 3: combine */
			display-mode = <1>;

			crtc0_out: port {
				crtc0_out_interface: endpoint@0 {
					remote-endpoint = <&parallel_in_crtc0>;
				};
			};
		};

		crtc1: crtc1 {
			compatible = "semidrive,kunlun-crtc";
			dpc-master = <&dc2>;
			/* 1 single, 2: duplicate, 3: combine */
			display-mode = <1>;

			crtc1_out: port {
				crtc1_out_interface: endpoint@0 {
					remote-endpoint = <&parallel_in_crtc1>;
				};
			};
		};

		crtc2: crtc2 {
			compatible = "semidrive,kunlun-crtc";
			dpc-master = <&dc3>;
			/* 1 single, 2: duplicate, 3: combine */
			display-mode = <1>;

			crtc2_out: port {
				crtc2_out_interface: endpoint@0 {
					remote-endpoint = <&parallel_in_crtc2>;
				};
			};
		};

		parallel0: parallel@0 {
			compatible = "semidrive, kunlun-display-parallel";
			status = "disabled";

			ports {
				#address-cells = <1>;
				#size-cells = <0>;
				parallel0_in: port@0 {
					parallel_in_crtc0: endpoint@0 {
						remote-endpoint = <&crtc0_out_interface>;
					};
				};

				parallel0_out: port@1 {
					#address-cells = <1>;
					#size-cells = <0>;
					reg = <1>;
					parallel_out_timing0: endpoint@0 {
						reg = <0>;
						remote-endpoint = <&parall_panel0_in>;
					};
				};
			};
		};

		parallel1: parallel@1 {
			compatible = "semidrive, kunlun-display-parallel";
			status = "disabled";

			ports {
				#address-cells = <1>;
				#size-cells = <0>;
				parallel1_in: port@0 {
					parallel_in_crtc1: endpoint@0 {
			remote-endpoint = <&crtc1_out_interface>;
					};
				};

				parallel1_out: port@1 {
					#address-cells = <1>;
					#size-cells = <0>;
					reg = <1>;
					parallel_out_timing1: endpoint@0 {
						reg = <0>;
			remote-endpoint = <&parall_panel1_in>;
					};
				};
			};
		};

		parallel2: parallel@2 {
			compatible = "semidrive, kunlun-display-parallel";
			status = "disabled";

			ports {
				#address-cells = <1>;
				#size-cells = <0>;
				parallel2_in: port@0 {
					parallel_in_crtc2: endpoint@0 {
			remote-endpoint = <&crtc2_out_interface>;
					};
				};

				parallel2_out: port@1 {
					#address-cells = <1>;
					#size-cells = <0>;
					reg = <1>;
					parallel_out_timing2: endpoint@0 {
						reg = <0>;
			remote-endpoint = <&parall_panel2_in>;
					};
				};
			};
		};

		lvds1: lvds1@30c50000 {
			compatible = "semidrive, kunlun-display-lvds";
			reg = <LVDS_BASE LVDS_RANGE>;
			lvds-select = <1>;
			dual-mode = <0>;
			lvds-combine = <0>;
			map-format = <1>;
			pixel-format = <1>;

			status = "disabled";

			ports {
				#address-cells = <1>;
				#size-cells = <0>;
				lvds0_in: port@0 {
					lvds_in_crtc0: endpoint@0 {
			remote-endpoint = <&crtc1_out_interface>;
					};
				};

				lvds0_out: port@1 {
					#address-cells = <1>;
					#size-cells = <0>;
					reg = <1>;
					lvds_out_timing0: endpoint@0 {
						reg = <0>;
				remote-endpoint = <&parall_panel1_in>;
					};
				};
			};
		};

		lvds2: lvds2@30c60000 {
			compatible = "semidrive, kunlun-display-lvds";
			reg = <LVDS_BASE LVDS_RANGE>;
			lvds-select = <2>;
			dual-mode = <0>;
			lvds-combine = <0>;
			map-format = <1>;
			pixel-format = <1>;

			status = "disabled";

			ports {
				#address-cells = <1>;
				#size-cells = <0>;
				lvds1_in: port@0 {
					lvds_in_crtc1: endpoint@0 {
				remote-endpoint = <&crtc2_out_interface>;
					};
				};

				lvds1_out: port@1 {
					#address-cells = <1>;
					#size-cells = <0>;
					reg = <1>;
					lvds_out_timing1: endpoint@0 {
						reg = <0>;
					remote-endpoint = <&parall_panel2_in>;
					};
				};
			};
		};

		dsi1: dsi1@30D60000 {
			compatible = "semidrive,dsi-host";
			reg = <0x0 0x30d60000 0x0 0x10000>;
			interrupts = <0 139 4>;
			status = "disabled";
			#address-cells = <1>;
			#size-cells = <0>;
			ports {

				dsi0_in: port@0 {
					dsi_in_crtc0: endpoint@0 {
						remote-endpoint = <&crtc0_out_interface>;
					};
				};
			};
		};

		ptimings0: parallel-timings@0 {
			compatible = "semidrive,panel-simple";
			status = "disabled";

			port {
				parall_panel0_in: endpoint {
					remote-endpoint = <&parallel_out_timing0>;
				};
			};

			dtimings0: display-timings {
			};
		};

		ptimings1: parallel-timings@1 {
			compatible = "semidrive,panel-simple";
			status = "disabled";

			port {
				parall_panel1_in: endpoint {
					remote-endpoint = <&lvds_out_timing0>;
				};
			};

			dtimings1: display-timings {
			};
		};

		ptimings2: parallel-timings@2 {
			compatible = "semidrive,panel-simple";
			status = "disabled";

			port {
				parall_panel2_in: endpoint {
					remote-endpoint = <&lvds_out_timing1>;
				};
			};

			dtimings2: display-timings {
			};
		};

		ptimings3: parallel-timings@3 {
			compatible = "semidrive,panel-simple";
			status = "disabled";

			dtimings3: display-timings {
			};
		};

		ethernet1: eth@30170000 {
			compatible = "semidrive,dwc-qos-ethernet";
			reg = <0x0 0x30170000 0x0 0x10000>;
			interrupts = <GIC_SPI 102 IRQ_TYPE_LEVEL_HIGH>;
			phy-handle = <&eth_phy1>;
			phy-mode = "rgmii";
			snps,force_sf_dma_mode;
			rx-fifo-depth = <0x2000>;
			tx-fifo-depth = <0x2000>;
			semidrive,multicast_filter_bins = <4>;
			semidrive,mcast_bits_log2 = <7>;
			status = "disabled";

			mdio1: mdio@1 {
				compatible = "snps,dwmac-mdio";
				#address-cells = <1>;
				#size-cells = <0>;
				//reset-gpios = <&port4a 27 GPIO_ACTIVE_LOW> ;//ospidata1 io27 ae24
				eth_phy1: ethernet-phy@1 {
					compatible = "ethernet-phy-ieee802.3-c22";
					reg = <0>;
				};
			};
		};

		ethernet2: eth@306A0000 {
			compatible = "semidrive,dwc-qos-ethernet";
			reg = <0x0 0x306A0000 0x0 0x10000>;
			interrupts = <GIC_SPI 105 IRQ_TYPE_LEVEL_HIGH>;
			clocks = <&ETH2_TX>, <&ETH2_TIMER_SEC>;
			clock-names = "stmmaceth", "ptp_ref";
			/* phy-handle = <&eth_phy2>; */
			phy-mode = "rgmii";
			snps,force_sf_dma_mode;
			snps,force_disable_asp;
			rx-fifo-depth = <0x2000>;
			tx-fifo-depth = <0x2000>;
			semidrive,multicast_filter_bins = <4>;
			semidrive,mcast_bits_log2 = <7>;
			status = "disabled";
			/*
			mdio2: mdio@2 {
				compatible = "snps,dwmac-mdio";
				#address-cells = <1>;
				#size-cells = <0>;

				eth_phy2: ethernet-phy@2 {
					compatible = "ethernet-phy-ieee802.3-c22";
					reg = <0>;
				};
			};
			*/

		fixed-link {
			speed = <1000>;
			full-duplex;

		   };
		};

		gpio4: gpio@30420000 {
			#address-cells = <1>;
			#size-cells = <0>;
			compatible = "semidrive,sdrv-gpio";
			reg = <0x0 0x30420000 0x0 0x10000>;
			status = "disabled";

			port4a: gpio-controller@0 {
				compatible = "semidrive,sdrv-gpio-port";
				gpio-controller;
				gpio-ranges = <&pinctrl 0 0 32>;
				#gpio-cells = <2>;
				nr-gpios = <32>;
				reg = <0>;
				interrupt-controller;
				#interrupt-cells = <2>;
				interrupts = <GIC_SPI 236 IRQ_TYPE_LEVEL_HIGH>;
			};

			port4b: gpio-controller@1 {
				compatible = "semidrive,sdrv-gpio-port";
				gpio-controller;
				gpio-ranges = <&pinctrl 0 32 32>;
				#gpio-cells = <2>;
				nr-gpios = <32>;
				reg = <1>;
				interrupt-controller;
				#interrupt-cells = <2>;
				interrupts = <GIC_SPI 237 IRQ_TYPE_LEVEL_HIGH>;
			};

			port4c: gpio-controller@2 {
				compatible = "semidrive,sdrv-gpio-port";
				gpio-controller;
				gpio-ranges = <&pinctrl 0 64 32>;
				#gpio-cells = <2>;
				nr-gpios = <32>;
				reg = <2>;
				interrupt-controller;
				#interrupt-cells = <2>;
				interrupts = <GIC_SPI 238 IRQ_TYPE_LEVEL_HIGH>;
			};

			port4d: gpio-controller@3 {
				compatible = "semidrive,sdrv-gpio-port";
				gpio-controller;
				gpio-ranges = <&pinctrl 0 96 32>;
				#gpio-cells = <2>;
				nr-gpios = <32>;
				reg = <3>;
				interrupt-controller;
				#interrupt-cells = <2>;
				interrupts = <GIC_SPI 239 IRQ_TYPE_LEVEL_HIGH>;
			};

			port4e: gpio-controller@4 {
				compatible = "semidrive,sdrv-gpio-port";
				gpio-controller;
				gpio-ranges = <&pinctrl 0 128 32>;
				#gpio-cells = <2>;
				nr-gpios = <32>;
				reg = <4>;
				interrupt-controller;
				#interrupt-cells = <2>;
				interrupts = <GIC_SPI 240 IRQ_TYPE_LEVEL_HIGH>;
			};

		};

		gpio5: gpio@30430000 {
			#address-cells = <1>;
			#size-cells = <0>;
			compatible = "semidrive,sdrv-gpio";
			reg = <0x0 0x30430000 0x0 0x10000>;
			status = "disabled";

			port5a: gpio-controller@0 {
				compatible = "semidrive,sdrv-gpio-port";
				gpio-controller;
				gpio-ranges = <&pinctrl 0 0 32>;
				#gpio-cells = <2>;
				nr-gpios = <32>;
				reg = <0>;
				interrupt-controller;
				#interrupt-cells = <2>;
				interrupts = <GIC_SPI 236 IRQ_TYPE_LEVEL_HIGH>;
			};

			port5b: gpio-controller@1 {
				compatible = "semidrive,sdrv-gpio-port";
				gpio-controller;
				gpio-ranges = <&pinctrl 0 32 32>;
				#gpio-cells = <2>;
				nr-gpios = <32>;
				reg = <1>;
				interrupt-controller;
				#interrupt-cells = <2>;
				interrupts = <GIC_SPI 237 IRQ_TYPE_LEVEL_HIGH>;
			};

			port5c: gpio-controller@2 {
				compatible = "semidrive,sdrv-gpio-port";
				gpio-controller;
				gpio-ranges = <&pinctrl 0 64 32>;
				#gpio-cells = <2>;
				nr-gpios = <32>;
				reg = <2>;
				interrupt-controller;
				#interrupt-cells = <2>;
				interrupts = <GIC_SPI 238 IRQ_TYPE_LEVEL_HIGH>;
			};
			port5d: gpio-controller@3 {
				compatible = "semidrive,sdrv-gpio-port";
				gpio-controller;
				gpio-ranges = <&pinctrl 0 96 32>;
				#gpio-cells = <2>;
				nr-gpios = <32>;
				reg = <3>;
				interrupt-controller;
				#interrupt-cells = <2>;
				interrupts = <GIC_SPI 239 IRQ_TYPE_LEVEL_HIGH>;
			};

			port5e: gpio-controller@4 {
				compatible = "semidrive,sdrv-gpio-port";
				gpio-controller;
				gpio-ranges = <&pinctrl 0 128 32>;
				#gpio-cells = <2>;
				nr-gpios = <32>;
				reg = <4>;
				interrupt-controller;
				#interrupt-cells = <2>;
				interrupts = <GIC_SPI 240 IRQ_TYPE_LEVEL_HIGH>;
			};

		};

		vce1: vce@34001000 {
			compatible = "semidrive,vce";
			reg = <0x0 0x34001000 0x0 0x1000>,
				  <0x0 0x00522000 0x0 0x2000>;
			reg-names = "ctrl_reg", "sram_base";
			ce_id = <1>;
			interrupts = <0 176 4>;
			status = "disabled";
		};

		vce2: vce@34002000 {
			compatible = "semidrive,vce";
			reg = <0x0 0x34002000 0x0 0x1000>,
				  <0x0 0x00524000 0x0 0x2000>;
			reg-names = "ctrl_reg", "sram_base";
			ce_id = <2>;
			interrupts = <0 177 4>;
			status = "disabled";
		};

		vce3: vce@34003000 {
			compatible = "semidrive,vce";
			reg = <0x0 0x34003000 0x0 0x1000>,
				  <0x0 0x00526000 0x0 0x2000>;
			reg-names = "ctrl_reg", "sram_base";
			ce_id = <3>;
			interrupts = <0 178 4>;
			status = "disabled";
		};

		rstgen: reset@38400000 {
			compatible = "semidrive,rstgen";
			#reset-cells = <1>;
			rstgen_module_base = <0x0 0x0>;
			rstgen_core_base = <0x0 0x0>;
			reg = <0x0 0x0 0x0 0x0>;
			rstgen_resource = <0>;
			status = "disable";
		};

		pcie1: pcie@31000000 {
			compatible = "semidrive,kunlun-pcie";
			reg = <0x0 0x31000000 0x0 0xE0000>,
			      <0x0 0x310e0000 0x0 0x20000>,
			      <0x0 0x31200000 0x0 0x10000>,
			      <0x0 0x31210000 0x0 0x10000>,
			      <0x0 0x34060000 0x0 0x20000>;
			reg-names = "dbi", "ctrl_ncr", "phy", "phy_ncr", "config";
			bus-range = <0x0  0xff>;
			#address-cells = <3>;
			#size-cells = <2>;
			device_type = "pci";
			ranges = <0x02000000 0x0 0x10000000 0x0 0x10000000 0x0 0x10000000
				  0x43000000 0x5 0x0 0x5 0x0 0x1 0x0>;
			num-lanes = <2>;

			#interrupt-cells = <1>;
			interrupts = <GIC_SPI 78 IRQ_TYPE_LEVEL_HIGH>;
			interrupt-names = "msi";
			interrupt-map-mask = <0xf800 0 0 7>;

			clocks = <&HIS_BUS_1>,
				 <&HIS_BUS_3_PCIE_PHY>,
				 <&HIS_BUS_2_PCIE1>,
				 <&HIS_BUS_3_PCIE1>;
			clock-names = "pcie_phy_ref", "pcie_phy_pclk",
						"pcie_aclk", "pcie_pclk";

			ref-clk = "internal,diffbuf_on";

			status = "disabled";

		};

		regctl: regctl@0x38414000 {
			compatible = "semidrive,reg-ctl";
			#regctl-cells = <1>;
			reg = <0x0 0x38414000 0x0 0x1000>,
				<0x0 0x38415000 0x0 0x1000>,
				<0x0 0x38416000 0x0 0x1000>,
				<0x0 0x38417000 0x0 0x1000>,
				<0x0 0x38418000 0x0 0x1000>,
				<0x0 0x38419000 0x0 0x1000>,
				<0x0 0x3841a000 0x0 0x1000>,
				<0x0 0x3841b000 0x0 0x1000>;
			reg-names = "SDRV_REG_ROM",
					"SDRV_REG_REMAP",
					"SDRV_REG_SDPE",
					"SDRV_REG_MCAL",
					"SDRV_REG_BOOTREASON",
					"SDRV_REG_HWID",
					"SDRV_REG_STATUS",
					"SDRV_REG_UNUSED";
			common_reg_base = <0x0 0x38414000>;
			status = "disable";
		};

		scr_sec: scr@0x38200000 {
			#scr-cells = <1>;
			compatible = "semidrive,scr";
			reg = <0x0 0x38200000 0x0 0x200000>;
			sdrv,scr_id = <SCR_SEC>;
			status = "disabled";
			sdrv,hwsem = <1>;
			sdrv,scr_signals =
				<SCR_SIGNAL(SCR_SEC__spi5_i_opmode)>,
				<SCR_SIGNAL(SCR_SEC__spi6_i_opmode)>,
				<SCR_SIGNAL(SCR_SEC__spi7_i_opmode)>,
				<SCR_SIGNAL(SCR_SEC__spi8_i_opmode)>,
				<SCR_SIGNAL(SCR_SEC__pio_i2s_sc_sdo_sdi_ctrl_5_0)>,
				<SCR_SIGNAL(SCR_SEC__mshc1_ddr_mode)>,
				<SCR_SIGNAL(SCR_SEC__mshc2_ddr_mode)>,
				<SCR_SIGNAL(SCR_SEC__mshc3_ddr_mode)>,
				<SCR_SIGNAL(SCR_SEC__mshc4_ddr_mode)>,
				<SCR_SIGNAL(SCR_SEC__vpu2_i_linebuffer_cfg_1_0)>;
		};

		ion: semidrive,ion {
			compatible = "semidrive,sdrv-ion";
			#address-cells = <1>;
			#size-cells = <0>;
			status = "disabled";
		};

		cooling_devices: cooling_devices {
			compatible = "simple-mfd";
			status = "disabled";

			cpufreq_cluster0: cpufreq_cluster0 {
				compatible = "semidrive, cpufreq-cooling";
				status = "okay";
				#cooling-cells = <2>;
				cluster_id = <0>;
			};

			cpucore_cluster0: cpucore_cluster0 {
				compatible = "semidrive, cpucore-cooling";
				status = "okay";
				#cooling-cells = <2>;
				cluster_id = <0>;
			};
		};

		pvt_sensor: pvt_sensor@0x30880000{
			compatible = "semidrive, kunlun-pvt-sensor";
			reg = <0x0 0x30880000 0x0 0x1000>;
			#thermal-sensor-cells = <1>;
			pvt_sensor_mode	= "temp";
			alarm_num = <1>;
			interrupts = <GIC_SPI 228 IRQ_TYPE_LEVEL_HIGH>;
			status = "disabled";
			alarm0 {
				alarm_hyst_type = "hyst_r";
				alarm_low_temp = <90000>;
				alarm_high_temp	= <100000>;
			};
		};

		thermal-zones{
			cpu_thermal_zone0{
				polling-delay-passive = <1000>;
				polling-delay = <2000>;
				thermal-sensors = <&pvt_sensor 0>;
				trips{
					cpu_trip0:t0{
						temperature = <100000>;
						type = "passive";
						hysteresis = <0>;
					};
					cpu_trip1:t1{
						temperature = <110000>;
						type = "passive";
						hysteresis = <0>;
					};
					cpu_trip2:t2{
						temperature = <120000>;
						type = "passive";
						hysteresis = <0>;
					};
					crt_trip0:t4{
						temperature = <125000>;
						type = "critical";
						hysteresis = <0>;
					};
				};
				cooling-maps {
					bind0 {
						contribution = <0>;
						trip = <&cpu_trip0>;
						cooling-device = <&cpufreq_cluster0 THERMAL_NO_LIMIT 2>;
					};
					bind1{
						contribution = <0>;
						trip = <&cpu_trip1>;
						cooling-device = <&cpufreq_cluster0 THERMAL_NO_LIMIT 3>;
					};
					bind2{
						contribution = <0>;
						trip = <&cpu_trip2>;
						cooling-device = <&cpucore_cluster0 THERMAL_NO_LIMIT 3>;
					};
				};
			};
		};

		rfkill: rfkill@0{
			compatible = "semidrive,sd-rfkill";
			status = "disabled";
		};

		sdrfkill: rfkill@1{
			compatible = "semidrive,sd-rfkill-v2";
			bluetooth-name="bt";
			bluetooth-reset-gpio=<0 0 0>;
			bluetooth-en-gpio=<0 0 0>;
			bluetooth-delay=<10>;
			wlan-name="wlan";
			wlan-reset-gpio=<0 0 0>;
			wlan-en-gpio=<0 0 0>;
			wlan-delay=<10>;
			gps-name="gps";
			gps-reset-gpio=<0 0 0>;
			gps-en-gpio=<0 0 0>;
			gps-delay=<10>;
			status = "disabled";
		};

		flexcan1: can@30030000 {
			compatible = "semidrive,flexcan";
			reg = <0x0 0x30030000 0x0 0x10000>;
			interrupts = <GIC_SPI 118 IRQ_TYPE_LEVEL_HIGH>;
			status = "disabled";
		};

		flexcan2: can@30040000 {
			compatible = "semidrive,flexcan";
			reg = <0x0 0x30040000 0x0 0x10000>;
			interrupts = <GIC_SPI 119 IRQ_TYPE_LEVEL_HIGH>;
			status = "disabled";
		};

		flexcan3: can@30050000 {
			compatible = "semidrive,flexcan";
			reg = <0x0 0x30050000 0x0 0x10000>;
			interrupts = <GIC_SPI 120 IRQ_TYPE_LEVEL_HIGH>;
			status = "disabled";
		};

		flexcan4: can@30060000 {
			compatible = "semidrive,flexcan";
			reg = <0x0 0x30060000 0x0 0x10000>;
			interrupts = <GIC_SPI 121 IRQ_TYPE_LEVEL_HIGH>;
			status = "disabled";
		};

		pfm: pfm@0x33020000 {
				compatible = "semidrive,pfm";
				reg = <0x0 0x33020000 0x0 0x10000>,
					  <0x0 0x45e00000 0x0 0x2000>;
				reg-names = "ctrl_reg", "ram_base";
				interrupts = <0 186 4>;
				time-window-mode = <1>;
				sdrv,group_info =
				<SDRV_PFM_GROUP_INFO_AP1>,
				<SDRV_PFM_GROUP_INFO_VDSP>,
				<SDRV_PFM_GROUP_INFO_CSI1_CSI3>,
				<SDRV_PFM_GROUP_INFO_DC1>,
				<SDRV_PFM_GROUP_INFO_DP1>,
				<SDRV_PFM_GROUP_INFO_GPU1>,
				<SDRV_PFM_GROUP_INFO_MJPEG>,
				<SDRV_PFM_GROUP_INFO_VPU1>,
				<SDRV_PFM_GROUP_INFO_ETH1_2>,
				<SDRV_PFM_GROUP_INFO_DMA5>,
				<SDRV_PFM_GROUP_INFO_G2D1>,
				<SDRV_PFM_GROUP_INFO_ALL>;
				status = "disabled";
		};
	};
};
